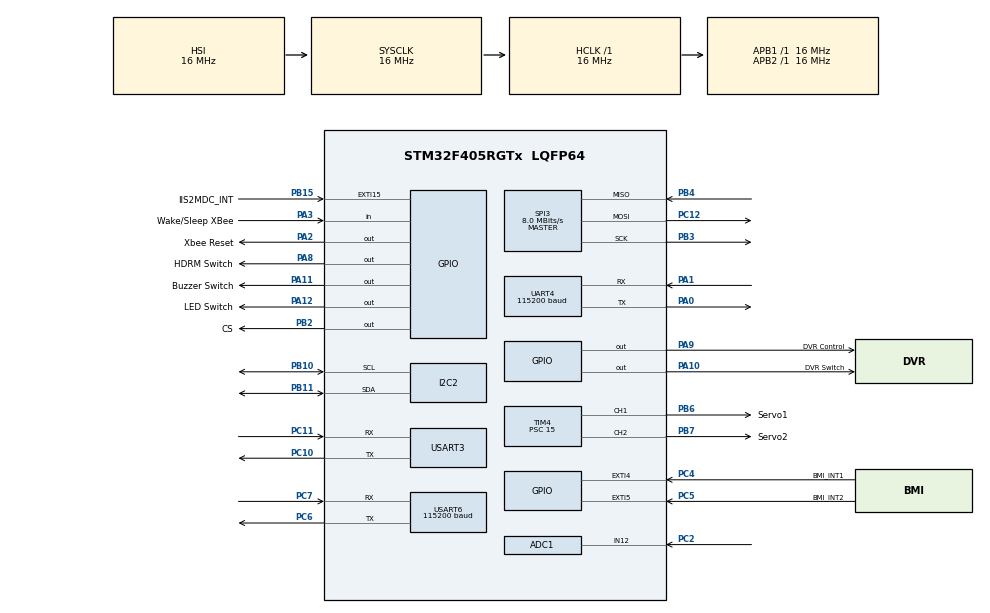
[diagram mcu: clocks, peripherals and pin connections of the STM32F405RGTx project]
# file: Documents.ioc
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ADC1.Channel-1\#ChannelRegularConversion=ADC_CHANNEL_12
ADC1.NbrOfConversionFlag=1
ADC1.Rank-1\#ChannelRegularConversion=1
ADC1.SamplingTime-1\#ChannelRegularConversion=ADC_SAMPLETIME_480CYCLES
ADC1.master=1
Dma.Request0=SPI3_RX
Dma.Request1=SPI3_TX
Dma.Request2=USART6_RX
Dma.Request3=UART4_RX
Dma.Request4=UART4_TX
Dma.SPI3_RX.0.Direction=DMA_PERIPH_TO_MEMORY
Dma.SPI3_RX.0.FIFOMode=DMA_FIFOMODE_DISABLE
Dma.SPI3_RX.0.Instance=DMA1_Stream0
Dma.SPI3_RX.0.MemDataAlignment=DMA_MDATAALIGN_BYTE
Dma.SPI3_RX.0.MemInc=DMA_MINC_ENABLE
Dma.SPI3_RX.0.Mode=DMA_NORMAL
Dma.SPI3_RX.0.PeriphDataAlignment=DMA_PDATAALIGN_BYTE
Dma.SPI3_RX.0.PeriphInc=DMA_PINC_DISABLE
Dma.SPI3_RX.0.Priority=DMA_PRIORITY_LOW
Dma.SPI3_TX.1.Direction=DMA_MEMORY_TO_PERIPH
Dma.SPI3_TX.1.FIFOMode=DMA_FIFOMODE_DISABLE
Dma.SPI3_TX.1.Instance=DMA1_Stream5
Dma.SPI3_TX.1.MemDataAlignment=DMA_MDATAALIGN_BYTE
Dma.SPI3_TX.1.MemInc=DMA_MINC_ENABLE
Dma.SPI3_TX.1.Mode=DMA_NORMAL
Dma.SPI3_TX.1.PeriphDataAlignment=DMA_PDATAALIGN_BYTE
Dma.SPI3_TX.1.PeriphInc=DMA_PINC_DISABLE
Dma.SPI3_TX.1.Priority=DMA_PRIORITY_LOW
Dma.UART4_RX.3.Direction=DMA_PERIPH_TO_MEMORY
Dma.UART4_RX.3.FIFOMode=DMA_FIFOMODE_DISABLE
Dma.UART4_RX.3.Instance=DMA1_Stream2
Dma.UART4_RX.3.MemDataAlignment=DMA_MDATAALIGN_BYTE
Dma.UART4_RX.3.MemInc=DMA_MINC_ENABLE
Dma.UART4_RX.3.Mode=DMA_CIRCULAR
Dma.UART4_RX.3.PeriphDataAlignment=DMA_PDATAALIGN_BYTE
Dma.UART4_RX.3.PeriphInc=DMA_PINC_DISABLE
Dma.UART4_RX.3.Priority=DMA_PRIORITY_HIGH
Dma.UART4_TX.4.Direction=DMA_MEMORY_TO_PERIPH
Dma.UART4_TX.4.FIFOMode=DMA_FIFOMODE_DISABLE
Dma.UART4_TX.4.Instance=DMA1_Stream4
Dma.UART4_TX.4.MemDataAlignment=DMA_MDATAALIGN_BYTE
Dma.UART4_TX.4.MemInc=DMA_MINC_ENABLE
Dma.UART4_TX.4.Mode=DMA_NORMAL
Dma.UART4_TX.4.PeriphDataAlignment=DMA_PDATAALIGN_BYTE
Dma.UART4_TX.4.PeriphInc=DMA_PINC_DISABLE
Dma.UART4_TX.4.Priority=DMA_PRIORITY_LOW
Dma.USART6_RX.2.Direction=DMA_PERIPH_TO_MEMORY
Dma.USART6_RX.2.FIFOMode=DMA_FIFOMODE_DISABLE
Dma.USART6_RX.2.Instance=DMA2_Stream1
Dma.USART6_RX.2.MemDataAlignment=DMA_MDATAALIGN_BYTE
Dma.USART6_RX.2.MemInc=DMA_MINC_ENABLE
Dma.USART6_RX.2.Mode=DMA_CIRCULAR
Dma.USART6_RX.2.PeriphDataAlignment=DMA_PDATAALIGN_BYTE
Dma.USART6_RX.2.PeriphInc=DMA_PINC_DISABLE
Dma.USART6_RX.2.Priority=DMA_PRIORITY_HIGH
FATFS._USE_LABEL=1
FATFS._USE_LFN=3
Mcu.Family=STM32F4
Mcu.Name=STM32F405RGTx
Mcu.Package=LQFP64
NVIC.DMA1_Stream0_IRQn=true\:0\:0\:false\:false\:true\:false\:true\:true
NVIC.DMA1_Stream2_IRQn=true\:1\:0\:false\:false\:true\:false\:true\:true
NVIC.DMA1_Stream4_IRQn=true\:1\:0\:false\:false\:true\:false\:true\:true
NVIC.DMA1_Stream5_IRQn=true\:0\:0\:false\:false\:true\:false\:true\:true
NVIC.DMA2_Stream1_IRQn=true\:1\:0\:false\:false\:true\:false\:true\:true
NVIC.PriorityGroup=NVIC_PRIORITYGROUP_4
NVIC.TIM6_DAC_IRQn=true\:15\:0\:false\:false\:true\:false\:true\:true
NVIC.TimeBase=TIM6_DAC_IRQn
NVIC.TimeBaseIP=TIM6
NVIC.UART4_IRQn=true\:1\:0\:false\:false\:true\:true\:true\:true
NVIC.USART6_IRQn=true\:1\:0\:false\:false\:true\:true\:true\:true
PA0-WKUP.GPIO_PuPd=GPIO_NOPULL
PA0-WKUP.Mode=Asynchronous
PA0-WKUP.Signal=UART4_TX
PA1.Mode=Asynchronous
PA1.Signal=UART4_RX
PA10.GPIO_Label=DVR Switch
PA10.Signal=GPIO_Output
PA11.GPIO_Label=Buzzer Switch
PA11.Signal=GPIO_Output
PA12.GPIO_Label=LED Switch
PA12.Signal=GPIO_Output
PA13.Mode=Serial_Wire
PA13.Signal=SYS_JTMS-SWDIO
PA14.Mode=Serial_Wire
PA14.Signal=SYS_JTCK-SWCLK
PA2.GPIO_Label=Xbee Reset
PA2.GPIO_ModeDefaultOutputPP=GPIO_MODE_OUTPUT_OD
PA2.PinState=GPIO_PIN_SET
PA2.Signal=GPIO_Output
PA3.GPIO_Label=Wake/Sleep XBee
PA3.Signal=GPIO_Input
PA8.GPIO_Label=HDRM Switch
PA8.Signal=GPIO_Output
PA9.GPIO_Label=DVR Control
PA9.Signal=GPIO_Output
PB10.Mode=I2C
PB10.Signal=I2C2_SCL
PB11.Mode=I2C
PB11.Signal=I2C2_SDA
PB15.GPIO_Label=IIS2MDC_INT
PB15.Signal=GPXTI15
PB2.GPIO_Label=CS
PB2.GPIO_Speed=GPIO_SPEED_FREQ_HIGH
PB2.PinState=GPIO_PIN_SET
PB2.Signal=GPIO_Output
PB3.Mode=Full_Duplex_Master
PB3.Signal=SPI3_SCK
PB4.Mode=Full_Duplex_Master
PB4.Signal=SPI3_MISO
PB6.GPIO_Label=Servo1
PB6.Signal=S_TIM4_CH1
PB7.GPIO_Label=Servo2
PB7.Signal=S_TIM4_CH2
PC10.Mode=Asynchronous
PC10.Signal=USART3_TX
PC11.Mode=Asynchronous
PC11.Signal=USART3_RX
PC12.Mode=Full_Duplex_Master
PC12.Signal=SPI3_MOSI
PC2.Signal=ADCx_IN12
PC4.GPIO_Label=BMI_INT1
PC4.Signal=GPXTI4
PC5.GPIO_Label=BMI_INT2
PC5.Signal=GPXTI5
PC6.Mode=Asynchronous
PC6.Signal=USART6_TX
PC7.Mode=Asynchronous
PC7.Signal=USART6_RX
PH0-OSC_IN.Mode=HSE-External-Oscillator
PH0-OSC_IN.Signal=RCC_OSC_IN
PH1-OSC_OUT.Mode=HSE-External-Oscillator
PH1-OSC_OUT.Signal=RCC_OSC_OUT
ProjectManager.HeapSize=0x200
ProjectManager.StackSize=0x400
ProjectManager.TargetToolchain=CMake
RCC.48MHZClocksFreq_Value=48000000
RCC.AHBFreq_Value=16000000
RCC.APB1Freq_Value=16000000
RCC.APB1TimFreq_Value=16000000
RCC.APB2Freq_Value=16000000
RCC.APB2TimFreq_Value=16000000
RCC.CortexFreq_Value=16000000
RCC.HCLKFreq_Value=16000000
RCC.HSE_VALUE=8000000
RCC.HSI_VALUE=16000000
RCC.LSE_VALUE=32768
RCC.RCC_RTC_Clock_Source_FROM_HSE=RCC_RTCCLKSOURCE_HSE_DIV25
RCC.SYSCLKFreq_VALUE=16000000
RCC.VCOOutputFreq_Value=192000000
RTC.SynchPrediv=249
SH.ADCx_IN12.0=ADC1_IN12,IN12
SH.S_TIM4_CH1.0=TIM4_CH1,PWM Generation1 CH1
SH.S_TIM4_CH2.0=TIM4_CH2,PWM Generation2 CH2
SPI3.CalculateBaudRate=8.0 MBits/s
SPI3.Direction=SPI_DIRECTION_2LINES
SPI3.Mode=SPI_MODE_MASTER
SPI3.VirtualType=VM_MASTER
TIM4.AutoReloadPreload=TIM_AUTORELOAD_PRELOAD_ENABLE
TIM4.Channel-PWM\ Generation1\ CH1=TIM_CHANNEL_1
TIM4.Channel-PWM\ Generation2\ CH2=TIM_CHANNEL_2
TIM4.Period=19999
TIM4.Prescaler=15
UART4.BaudRate=115200
UART4.VirtualMode=Asynchronous
USART3.VirtualMode=VM_ASYNC
USART6.BaudRate=115200
USART6.VirtualMode=VM_ASYNC
VP_FATFS_VS_Generic.Mode=User_defined
VP_RTC_VS_RTC_Activate.Mode=RTC_Enabled
VP_RTC_VS_RTC_Calendar.Mode=RTC_Calendar
VP_SYS_VS_tim6.Mode=TIM6
VP_TIM4_VS_ClockSourceINT.Mode=Internal
board=custom

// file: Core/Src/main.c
/* USER CODE BEGIN Header */
/**
  ******************************************************************************
  * @file           : main.c
  * @brief          : Main program body
  ******************************************************************************
  * @attention
  *
  * Copyright (c) 2026 STMicroelectronics.
  * All rights reserved.
  *
  * This software is licensed under terms that can be found in the LICENSE file
  * in the root directory of this software component.
  * If no LICENSE file comes with this software, it is provided AS-IS.
  *
  ******************************************************************************
  */
/* USER CODE END Header */
#include "main.h"
#include "fatfs.h"

/* USER CODE BEGIN Includes */
#include "App.h"
/* USER CODE END Includes */

ADC_HandleTypeDef hadc1;

I2C_HandleTypeDef hi2c2;

RTC_HandleTypeDef hrtc;

SPI_HandleTypeDef hspi3;
DMA_HandleTypeDef hdma_spi3_rx;
DMA_HandleTypeDef hdma_spi3_tx;

TIM_HandleTypeDef htim4;

UART_HandleTypeDef huart4;
UART_HandleTypeDef huart3;
UART_HandleTypeDef huart6;
DMA_HandleTypeDef hdma_uart4_rx;
DMA_HandleTypeDef hdma_uart4_tx;
DMA_HandleTypeDef hdma_usart6_rx;

void SystemClock_Config(void);
static void MX_GPIO_Init(void);
static void MX_DMA_Init(void);
static void MX_ADC1_Init(void);
static void MX_I2C2_Init(void);
static void MX_SPI3_Init(void);
static void MX_TIM4_Init(void);
static void MX_UART4_Init(void);
static void MX_USART6_UART_Init(void);
static void MX_USART3_UART_Init(void);
static void MX_RTC_Init(void);

int main(void)
{

  /* MCU Configuration--------------------------------------------------------*/

  /* Reset of all peripherals, Initializes the Flash interface and the Systick. */
  HAL_Init();

  /* Configure the system clock */
  SystemClock_Config();

  /* Initialize all configured peripherals */
  MX_GPIO_Init();
  MX_DMA_Init();
  MX_ADC1_Init();
  MX_I2C2_Init();
  MX_SPI3_Init();
  MX_TIM4_Init();
  MX_UART4_Init();
  MX_USART6_UART_Init();
  MX_USART3_UART_Init();
  MX_RTC_Init();
  /* USER CODE BEGIN 2 */
  App_Init();
  /* USER CODE END 2 */

  /* Infinite loop */
  /* USER CODE BEGIN WHILE */
  while (1)
  {
  App_RunOnce();
    /* USER CODE END WHILE */

  }
}

void SystemClock_Config(void)
{
  RCC_OscInitTypeDef RCC_OscInitStruct = {0};
  RCC_ClkInitTypeDef RCC_ClkInitStruct = {0};

  /** Configure the main internal regulator output voltage
  */
  __HAL_RCC_PWR_CLK_ENABLE();
  __HAL_PWR_VOLTAGESCALING_CONFIG(PWR_REGULATOR_VOLTAGE_SCALE1);

  /** Initializes the RCC Oscillators according to the specified parameters
  * in the RCC_OscInitTypeDef structure.
  */
  RCC_OscInitStruct.OscillatorType = RCC_OSCILLATORTYPE_HSI|RCC_OSCILLATORTYPE_LSI;
  RCC_OscInitStruct.HSIState = RCC_HSI_ON;
  RCC_OscInitStruct.HSICalibrationValue = RCC_HSICALIBRATION_DEFAULT;
  RCC_OscInitStruct.LSIState = RCC_LSI_ON;
  RCC_OscInitStruct.PLL.PLLState = RCC_PLL_NONE;
  if (HAL_RCC_OscConfig(&RCC_OscInitStruct) != HAL_OK)
  {
    Error_Handler();
  }

  /** Initializes the CPU, AHB and APB buses clocks
  */
  RCC_ClkInitStruct.ClockType = RCC_CLOCKTYPE_HCLK|RCC_CLOCKTYPE_SYSCLK
                              |RCC_CLOCKTYPE_PCLK1|RCC_CLOCKTYPE_PCLK2;
  RCC_ClkInitStruct.SYSCLKSource = RCC_SYSCLKSOURCE_HSI;
  RCC_ClkInitStruct.AHBCLKDivider = RCC_SYSCLK_DIV1;
  RCC_ClkInitStruct.APB1CLKDivider = RCC_HCLK_DIV1;
  RCC_ClkInitStruct.APB2CLKDivider = RCC_HCLK_DIV1;

  if (HAL_RCC_ClockConfig(&RCC_ClkInitStruct, FLASH_LATENCY_0) != HAL_OK)
  {
    Error_Handler();
  }
}

static void MX_ADC1_Init(void)
{

  ADC_ChannelConfTypeDef sConfig = {0};

  /** Configure the global features of the ADC (Clock, Resolution, Data Alignment and number of conversion)
  */
  hadc1.Instance = ADC1;
  hadc1.Init.ClockPrescaler = ADC_CLOCK_SYNC_PCLK_DIV2;
  hadc1.Init.Resolution = ADC_RESOLUTION_12B;
  hadc1.Init.ScanConvMode = DISABLE;
  hadc1.Init.ContinuousConvMode = DISABLE;
  hadc1.Init.DiscontinuousConvMode = DISABLE;
  hadc1.Init.ExternalTrigConvEdge = ADC_EXTERNALTRIGCONVEDGE_NONE;
  hadc1.Init.ExternalTrigConv = ADC_SOFTWARE_START;
  hadc1.Init.DataAlign = ADC_DATAALIGN_RIGHT;
  hadc1.Init.NbrOfConversion = 1;
  hadc1.Init.DMAContinuousRequests = DISABLE;
  hadc1.Init.EOCSelection = ADC_EOC_SINGLE_CONV;
  if (HAL_ADC_Init(&hadc1) != HAL_OK)
  {
    Error_Handler();
  }

  /** Configure for the selected ADC regular channel its corresponding rank in the sequencer and its sample time.
  */
  sConfig.Channel = ADC_CHANNEL_12;
  sConfig.Rank = 1;
  sConfig.SamplingTime = ADC_SAMPLETIME_480CYCLES;
  if (HAL_ADC_ConfigChannel(&hadc1, &sConfig) != HAL_OK)
  {
    Error_Handler();
  }

}

static void MX_I2C2_Init(void)
{

  hi2c2.Instance = I2C2;
  hi2c2.Init.ClockSpeed = 100000;
  hi2c2.Init.DutyCycle = I2C_DUTYCYCLE_2;
  hi2c2.Init.OwnAddress1 = 0;
  hi2c2.Init.AddressingMode = I2C_ADDRESSINGMODE_7BIT;
  hi2c2.Init.DualAddressMode = I2C_DUALADDRESS_DISABLE;
  hi2c2.Init.OwnAddress2 = 0;
  hi2c2.Init.GeneralCallMode = I2C_GENERALCALL_DISABLE;
  hi2c2.Init.NoStretchMode = I2C_NOSTRETCH_DISABLE;
  if (HAL_I2C_Init(&hi2c2) != HAL_OK)
  {
    Error_Handler();
  }

}

static void MX_RTC_Init(void)
{

  RTC_TimeTypeDef sTime = {0};
  RTC_DateTypeDef sDate = {0};

  /** Initialize RTC Only
  */
  hrtc.Instance = RTC;
  hrtc.Init.HourFormat = RTC_HOURFORMAT_24;
  hrtc.Init.AsynchPrediv = 127;
  hrtc.Init.SynchPrediv = 249;
  hrtc.Init.OutPut = RTC_OUTPUT_DISABLE;
  hrtc.Init.OutPutPolarity = RTC_OUTPUT_POLARITY_HIGH;
  hrtc.Init.OutPutType = RTC_OUTPUT_TYPE_OPENDRAIN;
  if (HAL_RTC_Init(&hrtc) != HAL_OK)
  {
    Error_Handler();
  }

  /** Initialize RTC and set the Time and Date
  */
  sTime.Hours = 0x0;
  sTime.Minutes = 0x0;
  sTime.Seconds = 0x0;
  sTime.DayLightSaving = RTC_DAYLIGHTSAVING_NONE;
  sTime.StoreOperation = RTC_STOREOPERATION_RESET;
  if (HAL_RTC_SetTime(&hrtc, &sTime, RTC_FORMAT_BCD) != HAL_OK)
  {
    Error_Handler();
  }
  sDate.WeekDay = RTC_WEEKDAY_MONDAY;
  sDate.Month = RTC_MONTH_JANUARY;
  sDate.Date = 0x1;
  sDate.Year = 0x0;

  if (HAL_RTC_SetDate(&hrtc, &sDate, RTC_FORMAT_BCD) != HAL_OK)
  {
    Error_Handler();
  }

}

static void MX_SPI3_Init(void)
{

  /* SPI3 parameter configuration*/
  hspi3.Instance = SPI3;
  hspi3.Init.Mode = SPI_MODE_MASTER;
  hspi3.Init.Direction = SPI_DIRECTION_2LINES;
  hspi3.Init.DataSize = SPI_DATASIZE_8BIT;
  hspi3.Init.CLKPolarity = SPI_POLARITY_LOW;
  hspi3.Init.CLKPhase = SPI_PHASE_1EDGE;
  hspi3.Init.NSS = SPI_NSS_SOFT;
  hspi3.Init.BaudRatePrescaler = SPI_BAUDRATEPRESCALER_2;
  hspi3.Init.FirstBit = SPI_FIRSTBIT_MSB;
  hspi3.Init.TIMode = SPI_TIMODE_DISABLE;
  hspi3.Init.CRCCalculation = SPI_CRCCALCULATION_DISABLE;
  hspi3.Init.CRCPolynomial = 10;
  if (HAL_SPI_Init(&hspi3) != HAL_OK)
  {
    Error_Handler();
  }

}

static void MX_TIM4_Init(void)
{

  TIM_ClockConfigTypeDef sClockSourceConfig = {0};
  TIM_MasterConfigTypeDef sMasterConfig = {0};
  TIM_OC_InitTypeDef sConfigOC = {0};

  htim4.Instance = TIM4;
  htim4.Init.Prescaler = 15;
  htim4.Init.CounterMode = TIM_COUNTERMODE_UP;
  htim4.Init.Period = 19999;
  htim4.Init.ClockDivision = TIM_CLOCKDIVISION_DIV1;
  htim4.Init.AutoReloadPreload = TIM_AUTORELOAD_PRELOAD_ENABLE;
  if (HAL_TIM_Base_Init(&htim4) != HAL_OK)
  {
    Error_Handler();
  }
  sClockSourceConfig.ClockSource = TIM_CLOCKSOURCE_INTERNAL;
  if (HAL_TIM_ConfigClockSource(&htim4, &sClockSourceConfig) != HAL_OK)
  {
    Error_Handler();
  }
  if (HAL_TIM_PWM_Init(&htim4) != HAL_OK)
  {
    Error_Handler();
  }
  sMasterConfig.MasterOutputTrigger = TIM_TRGO_RESET;
  sMasterConfig.MasterSlaveMode = TIM_MASTERSLAVEMODE_DISABLE;
  if (HAL_TIMEx_MasterConfigSynchronization(&htim4, &sMasterConfig) != HAL_OK)
  {
    Error_Handler();
  }
  sConfigOC.OCMode = TIM_OCMODE_PWM1;
  sConfigOC.Pulse = 0;
  sConfigOC.OCPolarity = TIM_OCPOLARITY_HIGH;
  sConfigOC.OCFastMode = TIM_OCFAST_DISABLE;
  if (HAL_TIM_PWM_ConfigChannel(&htim4, &sConfigOC, TIM_CHANNEL_1) != HAL_OK)
  {
    Error_Handler();
  }
  if (HAL_TIM_PWM_ConfigChannel(&htim4, &sConfigOC, TIM_CHANNEL_2) != HAL_OK)
  {
    Error_Handler();
  }
  HAL_TIM_MspPostInit(&htim4);

}

static void MX_UART4_Init(void)
{

  huart4.Instance = UART4;
  huart4.Init.BaudRate = 115200;
  huart4.Init.WordLength = UART_WORDLENGTH_8B;
  huart4.Init.StopBits = UART_STOPBITS_1;
  huart4.Init.Parity = UART_PARITY_NONE;
  huart4.Init.Mode = UART_MODE_TX_RX;
  huart4.Init.HwFlowCtl = UART_HWCONTROL_NONE;
  huart4.Init.OverSampling = UART_OVERSAMPLING_16;
  if (HAL_UART_Init(&huart4) != HAL_OK)
  {
    Error_Handler();
  }

}

static void MX_USART3_UART_Init(void)
{

  huart3.Instance = USART3;
  huart3.Init.BaudRate = 115200;
  huart3.Init.WordLength = UART_WORDLENGTH_8B;
  huart3.Init.StopBits = UART_STOPBITS_1;
  huart3.Init.Parity = UART_PARITY_NONE;
  huart3.Init.Mode = UART_MODE_TX_RX;
  huart3.Init.HwFlowCtl = UART_HWCONTROL_NONE;
  huart3.Init.OverSampling = UART_OVERSAMPLING_16;
  if (HAL_UART_Init(&huart3) != HAL_OK)
  {
    Error_Handler();
  }

}

static void MX_USART6_UART_Init(void)
{

  huart6.Instance = USART6;
  huart6.Init.BaudRate = 115200;
  huart6.Init.WordLength = UART_WORDLENGTH_8B;
  huart6.Init.StopBits = UART_STOPBITS_1;
  huart6.Init.Parity = UART_PARITY_NONE;
  huart6.Init.Mode = UART_MODE_TX_RX;
  huart6.Init.HwFlowCtl = UART_HWCONTROL_NONE;
  huart6.Init.OverSampling = UART_OVERSAMPLING_16;
  if (HAL_UART_Init(&huart6) != HAL_OK)
  {
    Error_Handler();
  }

}

static void MX_DMA_Init(void)
{

  /* DMA controller clock enable */
  __HAL_RCC_DMA1_CLK_ENABLE();
  __HAL_RCC_DMA2_CLK_ENABLE();

  /* DMA interrupt init */
  /* DMA1_Stream0_IRQn interrupt configuration */
  HAL_NVIC_SetPriority(DMA1_Stream0_IRQn, 0, 0);
  HAL_NVIC_EnableIRQ(DMA1_Stream0_IRQn);
  /* DMA1_Stream2_IRQn interrupt configuration */
  HAL_NVIC_SetPriority(DMA1_Stream2_IRQn, 1, 0);
  HAL_NVIC_EnableIRQ(DMA1_Stream2_IRQn);
  /* DMA1_Stream4_IRQn interrupt configuration */
  HAL_NVIC_SetPriority(DMA1_Stream4_IRQn, 1, 0);
  HAL_NVIC_EnableIRQ(DMA1_Stream4_IRQn);
  /* DMA1_Stream5_IRQn interrupt configuration */
  HAL_NVIC_SetPriority(DMA1_Stream5_IRQn, 0, 0);
  HAL_NVIC_EnableIRQ(DMA1_Stream5_IRQn);
  /* DMA2_Stream1_IRQn interrupt configuration */
  HAL_NVIC_SetPriority(DMA2_Stream1_IRQn, 1, 0);
  HAL_NVIC_EnableIRQ(DMA2_Stream1_IRQn);

}

static void MX_GPIO_Init(void)
{
  GPIO_InitTypeDef GPIO_InitStruct = {0};

  /* GPIO Ports Clock Enable */
  __HAL_RCC_GPIOH_CLK_ENABLE();
  __HAL_RCC_GPIOC_CLK_ENABLE();
  __HAL_RCC_GPIOA_CLK_ENABLE();
  __HAL_RCC_GPIOB_CLK_ENABLE();

  /*Configure GPIO pin Output Level */
  HAL_GPIO_WritePin(Xbee_Reset_GPIO_Port, Xbee_Reset_Pin, GPIO_PIN_SET);

  /*Configure GPIO pin Output Level */
  HAL_GPIO_WritePin(CS_GPIO_Port, CS_Pin, GPIO_PIN_SET);

  /*Configure GPIO pin Output Level */
  HAL_GPIO_WritePin(GPIOA, HDRM_Switch_Pin|DVR_Control_Pin|DVR_Switch_Pin|Buzzer_Switch_Pin
                          |LED_Switch_Pin, GPIO_PIN_RESET);

  /*Configure GPIO pin : Xbee_Reset_Pin */
  GPIO_InitStruct.Pin = Xbee_Reset_Pin;
  GPIO_InitStruct.Mode = GPIO_MODE_OUTPUT_OD;
  GPIO_InitStruct.Pull = GPIO_NOPULL;
  GPIO_InitStruct.Speed = GPIO_SPEED_FREQ_LOW;
  HAL_GPIO_Init(Xbee_Reset_GPIO_Port, &GPIO_InitStruct);

  /*Configure GPIO pin : Wake_Sleep_XBee_Pin */
  GPIO_InitStruct.Pin = Wake_Sleep_XBee_Pin;
  GPIO_InitStruct.Mode = GPIO_MODE_INPUT;
  GPIO_InitStruct.Pull = GPIO_NOPULL;
  HAL_GPIO_Init(Wake_Sleep_XBee_GPIO_Port, &GPIO_InitStruct);

  /*Configure GPIO pins : BMI_INT1_Pin BMI_INT2_Pin */
  GPIO_InitStruct.Pin = BMI_INT1_Pin|BMI_INT2_Pin;
  GPIO_InitStruct.Mode = GPIO_MODE_IT_RISING;
  GPIO_InitStruct.Pull = GPIO_NOPULL;
  HAL_GPIO_Init(GPIOC, &GPIO_InitStruct);

  /*Configure GPIO pin : CS_Pin */
  GPIO_InitStruct.Pin = CS_Pin;
  GPIO_InitStruct.Mode = GPIO_MODE_OUTPUT_PP;
  GPIO_InitStruct.Pull = GPIO_NOPULL;
  GPIO_InitStruct.Speed = GPIO_SPEED_FREQ_HIGH;
  HAL_GPIO_Init(CS_GPIO_Port, &GPIO_InitStruct);

  /*Configure GPIO pin : IIS2MDC_INT_Pin */
  GPIO_InitStruct.Pin = IIS2MDC_INT_Pin;
  GPIO_InitStruct.Mode = GPIO_MODE_IT_RISING;
  GPIO_InitStruct.Pull = GPIO_NOPULL;
  HAL_GPIO_Init(IIS2MDC_INT_GPIO_Port, &GPIO_InitStruct);

  /*Configure GPIO pins : HDRM_Switch_Pin DVR_Control_Pin DVR_Switch_Pin Buzzer_Switch_Pin
                           LED_Switch_Pin */
  GPIO_InitStruct.Pin = HDRM_Switch_Pin|DVR_Control_Pin|DVR_Switch_Pin|Buzzer_Switch_Pin
                          |LED_Switch_Pin;
  GPIO_InitStruct.Mode = GPIO_MODE_OUTPUT_PP;
  GPIO_InitStruct.Pull = GPIO_NOPULL;
  GPIO_InitStruct.Speed = GPIO_SPEED_FREQ_LOW;
  HAL_GPIO_Init(GPIOA, &GPIO_InitStruct);

}

void HAL_TIM_PeriodElapsedCallback(TIM_HandleTypeDef *htim)
{
  if (htim->Instance == TIM6)
  {
    HAL_IncTick();
  }
}

void Error_Handler(void)
{
  __disable_irq();
  while (1)
  {
  }
}
